# ATSAM4E16C device description
Architecture: CORTEX-M4; Family: SAM4; Series: SAM4E
Registers are 32-bit, read-write, no defined reset value unless marked. A register's access mark holds for its fields unless they carry their own. Offsets are from the block's base; [hi:lo] are bit positions; {n}, {i} and the like mark numbered series; 'fields as' and 'values as' point back to an identical list.

## CHIPID — Chip Identifier
Instances: CHIPID 0x400E0740
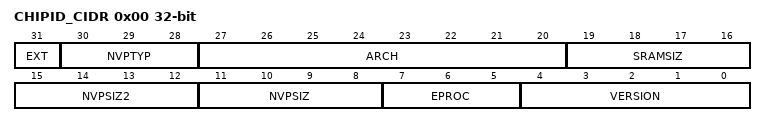
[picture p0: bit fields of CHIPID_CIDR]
0x00 CHIPID_CIDR ro — Chip ID Register
  [31] EXT — Extension Flag
  [30:28] NVPTYP — Nonvolatile Program Memory Type
    0=ROM; 1=ROMLESS (ROMless or on-chip Flash); 2=FLASH (Embedded Flash Memory); 3=ROM_FLASH (ROM and Embedded Flash MemoryNVPSIZ is ROM size NVPSIZ2 is Flash size); 4=SRAM (SRAM emulating ROM)
  [27:20] ARCH — Architecture Identifier
    25=AT91SAM9xx Series; 41=AT91SAM9XExx Series; 52=AT91x34 Series; 55=CAP7 (CAP7 Series); 57=CAP9 (CAP9 Series); 59=CAP11 (CAP11 Series); 60=SAM4E (SAM4E Series); 64=AT91x40 Series; 66=AT91x42 Series; 67=AT91x43 Series (WLCSP package); 85=AT91x55 Series; 96=AT91SAM7Axx Series; 97=AT91SAM7AQxx Series; 99=AT91x63 Series; 100=SAM4CxxC (SAM4CxC Series (100-pin version)); 102=SAM4CxxE (SAM4CxE Series (144-pin version)); 112=AT91SAM7Sxx Series; 113=AT91SAM7XCxx Series; 114=AT91SAM7SExx Series; 115=AT91SAM7Lxx Series; 117=AT91SAM7Xxx Series; 118=AT91SAM7SLxx Series; 128=SAM3UxC Series (100-pin version); 129=SAM3UxE Series (144-pin version); 131=SAM3AxC Series (100-pin version); 132=SAM3XxC Series (100-pin version); 133=SAM3XxE Series (144-pin version); 134=SAM3XxG Series (208/217-pin version); 136=SAM3SxASeries (48-pin version); 136=SAM4SxA Series (48-pin version); 137=SAM3SxB Series (64-pin version); 137=SAM4SxB Series (64-pin version); 138=SAM3SxC Series (100-pin version); 138=SAM4SxC Series (100-pin version); 146=AT91x92 Series; 147=SAM3NxA Series (48-pin version); 148=SAM3NxB Series (64-pin version); 149=SAM3NxC Series (100-pin version); 153=SAM3SDxB Series (64-pin version); 154=SAM3SDxC Series (100-pin version); 165=SAM5A; 176=SAM4LxA Series (48-pin version); 177=SAM4LxB Series (64-pin version); 178=SAM4LxC Series (100-pin version); 240=AT75Cxx Series
  [19:16] SRAMSIZ — Internal SRAM Size
    0=_48K (48 Kbytes); 1=_192K (192 Kbytes); 2=_2K (2 Kbytes); 3=_6K (6 Kbytes); 4=_24K (24 Kbytes); 5=_4K (4 Kbytes); 6=_80K (80 Kbytes); 7=_160K (160 Kbytes); 8=_8K (8 Kbytes); 9=_16K (16 Kbytes); 10=_32K (32 Kbytes); 11=_64K (64 Kbytes); 12=_128K (128 Kbytes); 13=_256K (256 Kbytes); 14=_96K (96 Kbytes); 15=_512K (512 Kbytes)
  [15:12] NVPSIZ2 — Second Nonvolatile Program Memory Size
    0=NONE; 1=_8K (8 Kbytes); 2=_16K (16 Kbytes); 3=_32K (32 Kbytes); 5=_64K (64 Kbytes); 7=_128K (128 Kbytes); 9=_256K (256 Kbytes); 10=_512K (512 Kbytes); 12=_1024K (1024 Kbytes); 14=_2048K (2048 Kbytes)
  [11:8] NVPSIZ — Nonvolatile Program Memory Size
    values as NVPSIZ2
  [7:5] EPROC — Embedded Processor
    1=ARM946ES; 2=ARM7TDMI; 3=CM3 (Cortex-M3); 4=ARM920T; 5=ARM926EJS; 6=CA5 (Cortex-A5); 7=CM4 (Cortex-M4)
  [4:0] VERSION — Version of the Device
0x04 CHIPID_EXID ro — Chip ID Extension Register
  [31:0] EXID — Chip ID Extension

## CMCC — Cortex M Cache Controller
Instances: CMCC 0x400C4000
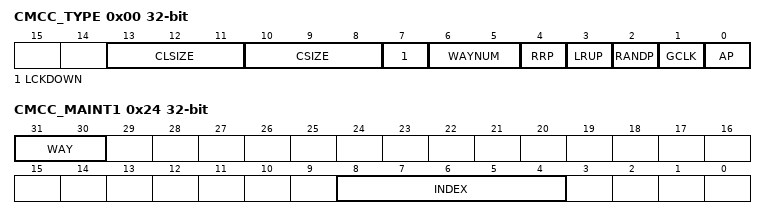
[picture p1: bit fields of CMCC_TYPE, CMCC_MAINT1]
0x00 CMCC_TYPE ro — Cache Type Register
  [13:11] CLSIZE — Cache Size
    0=CLSIZE_1KB (4 bytes); 1=CLSIZE_2KB (8 bytes); 2=CLSIZE_4KB (16 bytes); 3=CLSIZE_8KB (32 bytes)
  [10:8] CSIZE — Cache Size
    0=CSIZE_1KB (Cache Size 1 Kbytes); 1=CSIZE_2KB (Cache Size 2 Kbytes); 2=CSIZE_4KB (Cache Size 4 Kbytes); 3=CSIZE_8KB (Cache Size 8 Kbytes)
  [7] LCKDOWN — Lock Down Supported
  [6:5] WAYNUM — Number of Way
    0=DMAPPED (Direct Mapped Cache); 1=ARCH2WAY (2-WAY set associative); 2=ARCH4WAY (4-WAY set associative); 3=ARCH8WAY (8-WAY set associative)
  [4] RRP — Random Selection Policy Supported
  [3] LRUP — Least Recently Used Policy Supported
  [2] RANDP — Random Selection Policy Supported
  [1] GCLK — Dynamic Clock Gating Supported
  [0] AP — Access Port Access Allowed
0x04 CMCC_CFG — Cache Configuration Register
  [0] GCLKDIS — Disable Clock Gating
0x08 CMCC_CTRL wo — Cache Control Register
  [0] CEN — Cache Controller Enable
0x0C CMCC_SR ro — Cache Status Register
  [0] CSTS — Cache Controller Status
0x20 CMCC_MAINT0 wo — Cache Maintenance Register 0
  [0] INVALL — Cache Controller Invalidate All
0x24 CMCC_MAINT1 wo — Cache Maintenance Register 1
  [31:30] WAY — Invalidate Way
    {v}=Way {v} is selection for index invalidation (v=0..3)
  [8:4] INDEX — Invalidate Index
0x28 CMCC_MCFG — Cache Monitor Configuration Register
  [1:0] MODE — Cache Controller Monitor Counter Mode
    0=CYCLE_COUNT (Cycle counter); 1=IHIT_COUNT (Instruction hit counter); 2=DHIT_COUNT (Data hit counter)
0x2C CMCC_MEN — Cache Monitor Enable Register
  [0] MENABLE — Cache Controller Monitor Enable
0x30 CMCC_MCTRL wo — Cache Monitor Control Register
  [0] SWRST — Monitor
0x34 CMCC_MSR ro — Cache Monitor Status Register
  [31:0] EVENT_CNT — Monitor Event Counter
